# D2522AA register map
Vendor: Dialog; Series: D2522AA; File version: 1.2
CPU: CM0 r1p0, little endian, MPU, FPU, 3 interrupt priority bits
Registers are 32-bit, read-write, reset 0x0 unless marked. A register's access mark holds for its fields unless they carry their own. Offsets are from the block's base; [hi:lo] are bit positions; <NAME> marks a mode.

## lra2522_busif_00 — lra2522_busif_00 registers
Base 0x50030A00
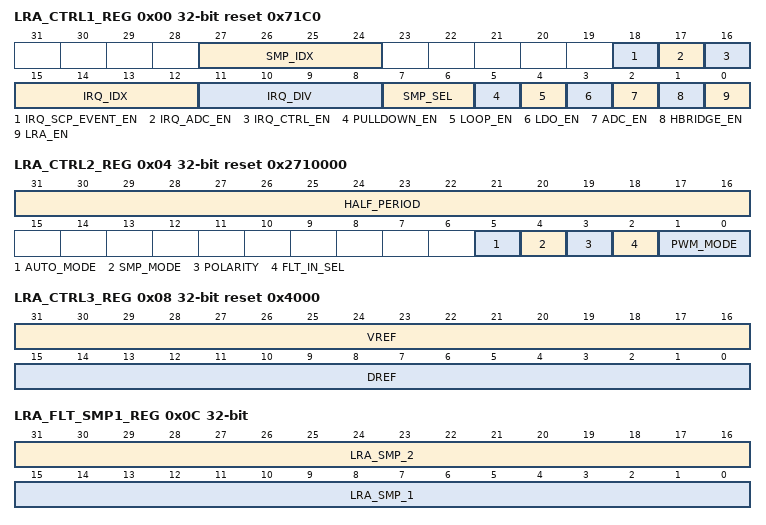
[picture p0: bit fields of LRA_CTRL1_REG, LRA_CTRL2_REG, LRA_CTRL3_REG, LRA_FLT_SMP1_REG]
0x00 LRA_CTRL1_REG reset 0x71C0 — General Purpose LRA Control Register
  [27:24] SMP_IDX ro — Current bin index (0-15). Check if equal to IRQ_IDX before and/or after updating HALF_PERIOD with ISR.
  [18] IRQ_SCP_EVENT_EN — 0 = interrupt scp event disabled 1 = interupt scp event enabled
  [17] IRQ_ADC_EN — 0 = interrupt adc disabled 1 = interupt adc enabled
  [16] IRQ_CTRL_EN — 0 = interrupt controller disabled 1 = interupt controller enabled
  [15:12] IRQ_IDX — At which sample index an IRQ will be generated (0-15). When IRQ_IDX < 8, IRQs are generated at both half cycles (IRQ_IDX and IRQ_IDX+8), otherwise only in the second half cycle.
  [11:8] IRQ_DIV — Divider value of the interrupt request. Number of LRA/ERM periods, between successive IRQs. 0,1=every (half) cycle, depending on IRQ_IDX; 2=every second cycle, IRQ at the end of first or both half cycles (based on IRQ_IDX), etc.
  [7:6] SMP_SEL — Select which samples to store for the resonance control algorithm. 0=Sense voltage after down-sampling 1=Error voltage (after subtraction of VREF and down-sampled sense voltgae input) 2=Duty cycle signal after loop-filter 3=Duty cycle signal after summation with DREF
  [5] PULLDOWN_EN — LXP and LXN node pull down enbale, when SC_EVENT=0 && LOOP_EN=0
  [4] LOOP_EN — 0=disable loop 1=enable loop
  [3] LDO_EN — 0=lra ldo disabled 1=lra ldo enabled
  [2] ADC_EN — 0=lra adc disabled 1=lra adc enabled
  [1] HBRIDGE_EN — 0=hbridge disabled 1=hbridge enabled
  [0] LRA_EN — 0=lra controller disabled 1=lra controller enabled
0x04 LRA_CTRL2_REG reset 0x2710000 (reset mask 0x7FFFFFFF) — General Purpose LRA Control Register
  [31:16] HALF_PERIOD — Half of the LRA period, in units of 4 ms (= 125 kHz divided by the resonant frequency of the LRA).
  [5] AUTO_MODE — Automatic frequency control (0=disabled;, 1=enabled, not yet implemented)
  [4] SMP_MODE — Sampling mode for data aiding automatic resonance control (0=averaging, 1=last sample)
  [3] POLARITY — Polarity of the square wave (0=normal; 1=inverted); Use for rapid stop.
  [2] FLT_IN_SEL — 0 = normal operation 1 = ADC output overruled by register value TBD
  [1:0] PWM_MODE — PWM pulse placement: 0=middle, 1=left, 2=right, 3=alternate
0x08 LRA_CTRL3_REG reset 0x4000 (reset mask 0x7FFFFFFF) — General Purpose LRA Control Register
  [31:16] VREF — Voltage reference for haptic feedback driver (1 bit sign + 7 bits integer + 8 bits fractional. (range -128 ... +127.99). The voltage is computed based on the desired reference current (IREF) that flows into the haptic device. VREF = IREF*TRIM_GAIN*128/2.4, with IREF in Amperes and TRIM_GAIN = 6, 8 (default), 10 or 12 as defined in LRA_BRD_HS_REG.
  [15:0] DREF — Duty cycle reference, start value from which the current control loop settles (1 sign bit, 7 integer bits, 8 fractional bits, -128 ... +127.99). Valid settings 5% through 95% (0x0666 - 0x799A).
0x0C LRA_FLT_SMP1_REG (reset mask 0x7FFFFFFF) — LRA Sample Register
  [31:16] LRA_SMP_2 ro — Second sample in first half-cycle used for resonance control algorithm.
  [15:0] LRA_SMP_1 ro — First sample in first half-cycle used for resonance control algorithm.
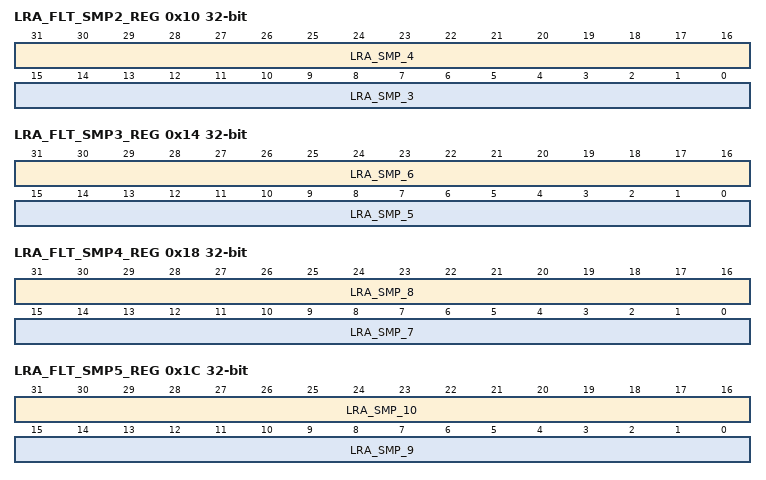
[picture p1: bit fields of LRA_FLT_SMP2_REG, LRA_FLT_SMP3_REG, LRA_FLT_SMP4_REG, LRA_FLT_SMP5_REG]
0x10 LRA_FLT_SMP2_REG (reset mask 0x7FFFFFFF) — LRA Sample Register
  [31:16] LRA_SMP_4 ro — Fourth sample in first half-cycle used for resonance control algorithm.
  [15:0] LRA_SMP_3 ro — Third sample in first half-cycle used for resonance control algorithm.
0x14 LRA_FLT_SMP3_REG (reset mask 0x7FFFFFFF) — LRA Sample Register
  [31:16] LRA_SMP_6 ro — Sixth sample in first half-cycle used for resonance control algorithm.
  [15:0] LRA_SMP_5 ro — Fifth sample in first half-cycle used for resonance control algorithm.
0x18 LRA_FLT_SMP4_REG (reset mask 0x7FFFFFFF) — LRA Sample Register
  [31:16] LRA_SMP_8 ro — Eighth sample in first half-cycle used for resonance control algorithm.
  [15:0] LRA_SMP_7 ro — Seventh sample in first half-cycle used for resonance control algorithm.
0x1C LRA_FLT_SMP5_REG (reset mask 0x7FFFFFFF) — LRA Sample Register
  [31:16] LRA_SMP_10 ro — Second sample in second half-cycle used for resonance control algorithm.
  [15:0] LRA_SMP_9 ro — First sample in second half-cycle used for resonance control algorithm.
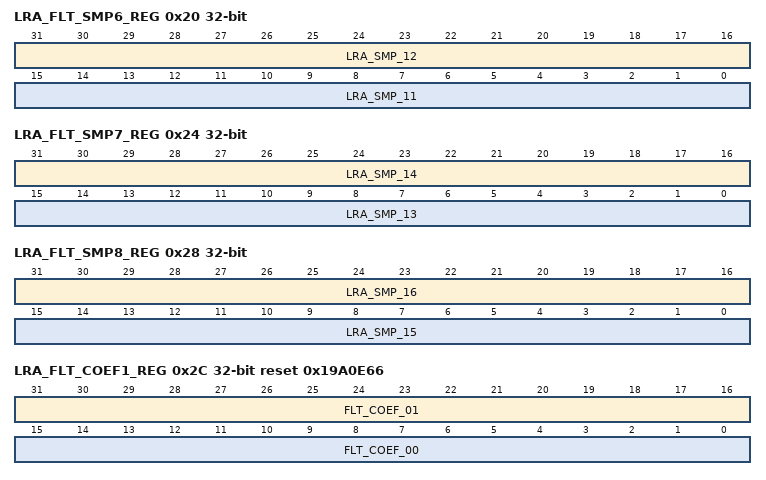
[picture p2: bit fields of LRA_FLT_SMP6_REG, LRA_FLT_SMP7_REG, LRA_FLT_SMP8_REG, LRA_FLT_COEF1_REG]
0x20 LRA_FLT_SMP6_REG (reset mask 0x7FFFFFFF) — LRA Sample Register
  [31:16] LRA_SMP_12 ro — Fourth sample in second half-cycle used for resonance control algorithm.
  [15:0] LRA_SMP_11 ro — Third sample in second half-cycle used for resonance control algorithm.
0x24 LRA_FLT_SMP7_REG (reset mask 0x7FFFFFFF) — LRA Sample Register
  [31:16] LRA_SMP_14 ro — Sixth sample in second half-cycle used for resonance control algorithm.
  [15:0] LRA_SMP_13 ro — Fifth sample in second half-cycle used for resonance control algorithm.
0x28 LRA_FLT_SMP8_REG (reset mask 0x7FFFFFFF) — LRA Sample Register
  [31:16] LRA_SMP_16 ro — Eighth sample in second half-cycle used for resonance control algorithm.
  [15:0] LRA_SMP_15 ro — Seventh sample in second half-cycle used for resonance control algorithm.
0x2C LRA_FLT_COEF1_REG reset 0x19A0E66 (reset mask 0x7FFFFFFF) — LRA Filter Coefficient Register
  [31:16] FLT_COEF_01 — Loop filter state-space coefficient a12 (1 sign bit, 1 integer bit, 14 fractional bits, range -2.000 .. +1.999).
  [15:0] FLT_COEF_00 — Loop filter state-space coefficient a11 (1 sign bit, 1 integer bit, 14 fractional bits, range -2.000 .. +1.999).
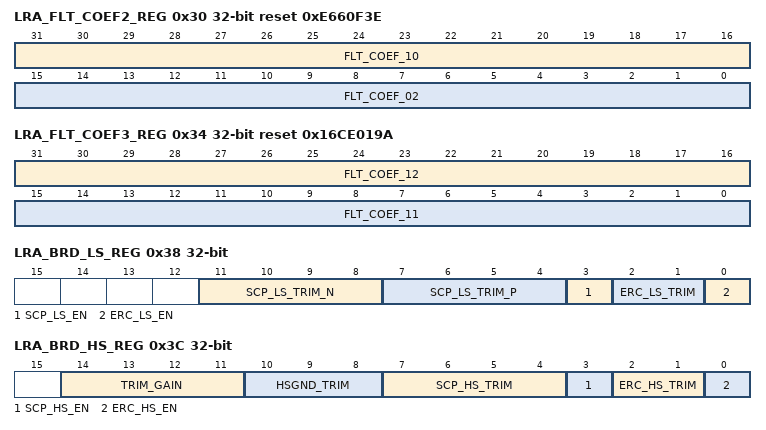
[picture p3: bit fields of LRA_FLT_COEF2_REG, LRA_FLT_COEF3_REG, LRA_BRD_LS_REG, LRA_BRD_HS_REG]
0x30 LRA_FLT_COEF2_REG reset 0xE660F3E (reset mask 0x7FFFFFFF) — LRA Filter Coefficient Register
  [31:16] FLT_COEF_10 — Loop filter state-space coefficient a21 (1 sign bit, 1 integer bit, 14 fractional bits, range -2.000 .. +1.999).
  [15:0] FLT_COEF_02 — Loop filter state-space coefficient b1 (1 sign bit, 1 integer bit, 14 fractional bits, range -2.000 .. +1.999).
0x34 LRA_FLT_COEF3_REG reset 0x16CE019A (reset mask 0x7FFFFFFF) — LRA Filter Coefficient Register
  [31:16] FLT_COEF_12 — Loop filter state-space coefficient b2 (1 sign bit, 1 integer bit, 14 fractional bits, range -2.000 .. +1.999).
  [15:0] FLT_COEF_11 — Loop filter state-space coefficient a22 (1 sign bit, 1 integer bit, 14 fractional bits, range -2.000 .. +1.999).
0x38 LRA_BRD_LS_REG — LRA Bridge Register
  [11:8] SCP_LS_TRIM_N — LSN short-circuit protection limit trimming
  [7:4] SCP_LS_TRIM_P — LSP short-circuit protection limit trimming
  [3] SCP_LS_EN — LS short-circuit protection enable
  [2:1] ERC_LS_TRIM — LS edge-rate control trimming. High-to-Low switching slewing: 00: 25 MV/s 01: 50 MV/s 10: 75 MV/s 11: 100 MV/s
  [0] ERC_LS_EN — LS edge-rate control enable
0x3C LRA_BRD_HS_REG — LRA Bridge Register
  [14:11] TRIM_GAIN — Current-sensing amplifier gain settings: 0001: x6 0010: x8 0100: x10 1000: x12
  [10:8] HSGND_TRIM
  [7:4] SCP_HS_TRIM — HS short-circuit protection limit trimming
  [3] SCP_HS_EN — HS short-circuit protection enable
  [2:1] ERC_HS_TRIM — HS edge-rate control trimming. Lowto-High switching slewing: 00: 25 MV/s 01: 50 MV/s 10: 75 MV/s 11: 100 MV/s
  [0] ERC_HS_EN — HS edge-rate control enable
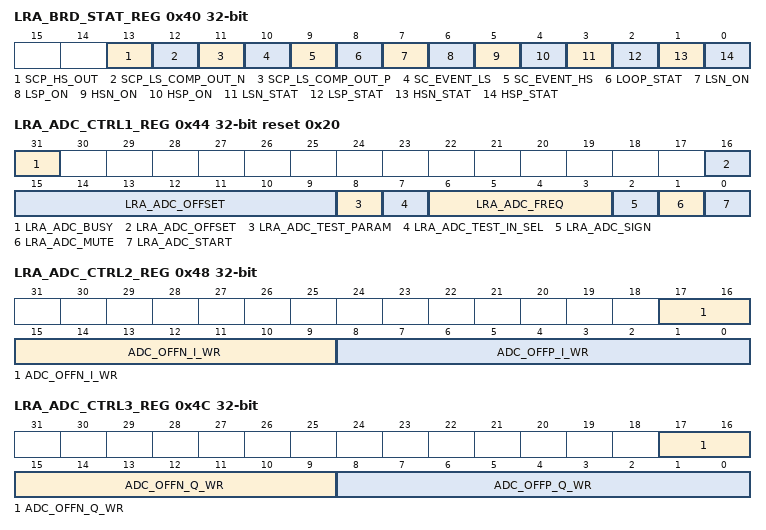
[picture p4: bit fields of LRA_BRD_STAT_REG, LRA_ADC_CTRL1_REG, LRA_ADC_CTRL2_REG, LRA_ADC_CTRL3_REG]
0x40 LRA_BRD_STAT_REG — LRA Bridge Staus Register
  [13] SCP_HS_OUT ro — HS short circuit comparator output
  [12] SCP_LS_COMP_OUT_N ro — LSN short circuit comparator output
  [11] SCP_LS_COMP_OUT_P ro — LSP short circuit comparator output
  [10] SC_EVENT_LS ro — 1: LS short-circuit event detected 0: no LS short-circuit event detected
  [9] SC_EVENT_HS ro — 1: HS short-circuit event detected 0: no HS short-circuit event detected
  [8] LOOP_STAT ro — 1: Loop saturation detected 0: Loop not saturated
  [7] LSN_ON ro — LSN control status
  [6] LSP_ON ro — LSP control status
  [5] HSN_ON ro — HSN control status
  [4] HSP_ON ro — HSP control status
  [3] LSN_STAT ro — LSN power FET gate actual status
  [2] LSP_STAT ro — LSP power FET gate actual status
  [1] HSN_STAT ro — HSN power FET gate actual status
  [0] HSP_STAT ro — HSP power FET gate actual status
0x44 LRA_ADC_CTRL1_REG reset 0x20 (reset mask 0x7FFFFFFF) — General Purpose ADC Control Register
  [31] LRA_ADC_BUSY ro — 0:ADC conversion ready. 1:ADC conversion in progress.
  [16:9] LRA_ADC_OFFSET — ADC offset signed value
  [8] LRA_ADC_TEST_PARAM — Select which inputs will be enabled on the ADC. 0,1 = normal inputs (i.e. both I and Q inputs connected to LRA-current-sense voltage source) 2 = I channel connected to the analog input testbus on PORTS TBD, Q channel is muted. 3 =QI channel connected to the analog input testbus on PORTS TBD, I channel is muted. Note: The LRA_ADC_CTRL1_REG[ADC_MUTE] field takes precedence over this test functionality.
  [7] LRA_ADC_TEST_IN_SEL — Select analog testbus on ADC input.
  [6:3] LRA_ADC_FREQ — ADC clock divider
  [2] LRA_ADC_SIGN — Change polarity of ADC input
  [1] LRA_ADC_MUTE — 0: Normal operation 1: Short the inputs of the ADC (used for DC offset cal)
  [0] LRA_ADC_START wo — 0: ADC conversion ready. 1: If a 1 is written, the ADC starts a conversion. After the conversion this bit will be set to 0 and the GP_ADC_INT bit will be set. It is not allowed to write this bit while it is not (yet) zero.
0x48 LRA_ADC_CTRL2_REG — Haptic Feedback Driver Current Sense ADC Control Register 2
  [17:9] ADC_OFFN_I_WR — External value for the DC offset compensation in the I path negative side. With common mode input voltage at Vpwrp/2, this value is 512-ADC_OFFP_Q_WR.
  [8:0] ADC_OFFP_I_WR — External value for the DC offset compensation in the I path positive side.
0x4C LRA_ADC_CTRL3_REG — Haptic Feedback Driver Current Sense ADC Control Register 3
  [17:9] ADC_OFFN_Q_WR — External value for the DC offset compensation in the Q path negative side. With common mode input voltage at Vpwrp/2, this value is 512-ADC_OFFP_Q_WR.
  [8:0] ADC_OFFP_Q_WR — External value for the DC offset compensation in the Q path positive side.
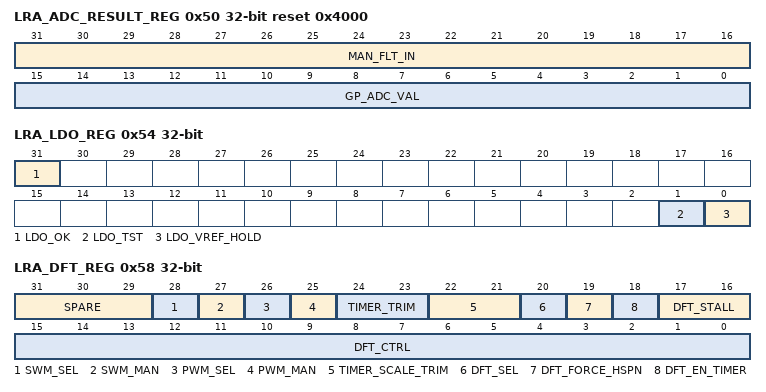
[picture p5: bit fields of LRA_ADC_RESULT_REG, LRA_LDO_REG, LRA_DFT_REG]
0x50 LRA_ADC_RESULT_REG reset 0x4000 (reset mask 0x7FFFFFFF) — General Purpose ADC Result Register
  [31:16] MAN_FLT_IN — Manual value to replace the ADC output. Select its use by FLT_IN_SEL.
  [15:0] GP_ADC_VAL ro — Returns the 10 up to 16 bits linear value of the last AD conversion. The upper 10 bits are always valid, the lower 6 bits are only valid in case oversampling has been applied. Two samples results in one extra bit and 64 samples results in six extra bits.
0x54 LRA_LDO_REG (reset mask 0x7FFFFFFF) — LRA LDO Regsiter
  [31] LDO_OK ro — 0: LDO not yet ok 1: LDO voltage is ready
  [1] LDO_TST — When set to 1, LDO output is connected to the testbus through a test switch
  [0] LDO_VREF_HOLD — 0: Indicates that the reference input is tracked, 1: Indicates that the reference input is sampled
0x58 LRA_DFT_REG (reset mask 0x7FFFFFFF) — LRA test Register
  [31:29] SPARE — spare registers bits , currently not used
  [28] SWM_SEL — 0=use SWM from controller 1=use SWM_MAN
  [27] SWM_MAN — swm manual
  [26] PWM_SEL — 0=use PWM from controller 1=use PWM_MAN
  [25] PWM_MAN — pwm manual
  [24:23] TIMER_TRIM — 20ns unit delay cell trimming bits
  [22:21] TIMER_SCALE_TRIM — Selection of delay of MAG and DEMAG signal: 00: 60ns 01: 80ns 10: 100ns 11: 120ns
  [20] DFT_SEL
  [19] DFT_FORCE_HSPN — Force HSP and HSN power FETs on: 0: not actived 1: HSP and HSN are forced on
  [18] DFT_EN_TIMER — Enable for the timer trimming
  [17:16] DFT_STALL — Force state machine in a certain state: 00: No test 01: High-Z 10: Mag 11: Demag
  [15:0] DFT_CTRL — Selection of test bus connection
